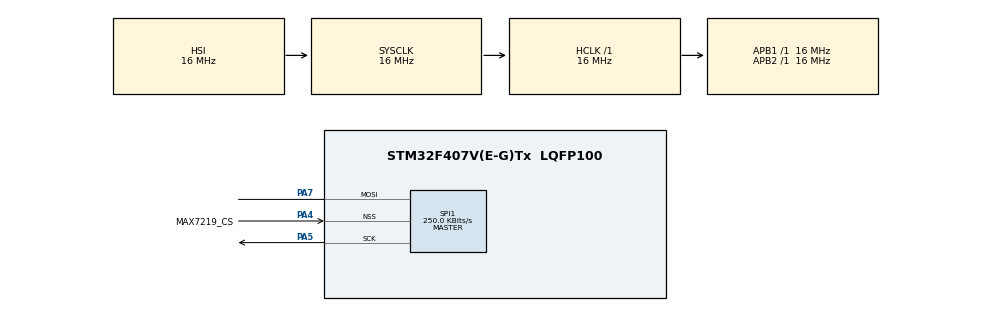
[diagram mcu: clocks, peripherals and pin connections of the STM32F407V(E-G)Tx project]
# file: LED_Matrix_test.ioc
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Mcu.Family=STM32F4
RCC.CortexFreq_Value=16000000
PA7.Mode=Simplex_Bidirectional_Master
SPI1.VirtualType=VM_MASTER
ProjectManager.StackSize=0x400
ProjectManager.TargetToolchain=STM32CubeIDE
PA4.Mode=NSS_Signal_Hard_Input
SPI1.Direction=SPI_DIRECTION_1LINE
SPI1.CalculateBaudRate=250.0 KBits/s
RCC.LSE_VALUE=32768
RCC.AHBFreq_Value=16000000
PA5.Signal=SPI1_SCK
RCC.HSE_VALUE=25000000
board=custom
RCC.VCOOutputFreq_Value=192000000
RCC.APB2Freq_Value=16000000
SPI1.Mode=SPI_MODE_MASTER
SPI1.VirtualNSS=VM_NSSHARD
Mcu.Name=STM32F407V(E-G)Tx
PA4.Signal=SPI1_NSS
RCC.SYSCLKFreq_VALUE=16000000
Mcu.Package=LQFP100
ProjectManager.HeapSize=0x200
RCC.HSI_VALUE=16000000
NVIC.PriorityGroup=NVIC_PRIORITYGROUP_4
RCC.APB1Freq_Value=16000000
SPI1.BaudRatePrescaler=SPI_BAUDRATEPRESCALER_64
PA4.GPIO_Label=MAX7219_CS
PA7.Signal=SPI1_MOSI
PA5.Mode=Simplex_Bidirectional_Master

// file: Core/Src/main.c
/* USER CODE BEGIN Header */
/**
  ******************************************************************************
  * @file           : main.c
  * @brief          : Main program body
  ******************************************************************************
  * @attention
  *
  * <h2><center>&copy; Copyright (c) 2021 STMicroelectronics.
  * All rights reserved.</center></h2>
  *
  * This software component is licensed by ST under BSD 3-Clause license,
  * the "License"; You may not use this file except in compliance with the
  * License. You may obtain a copy of the License at:
  *                        opensource.org/licenses/BSD-3-Clause
  *
  ******************************************************************************
  */
/* USER CODE END Header */
#include "main.h"

SPI_HandleTypeDef hspi1;

void SystemClock_Config(void);
static void MX_GPIO_Init(void);
static void MX_SPI1_Init(void);
/* USER CODE BEGIN PFP */
MAX7219_STATUS MAX7219_SetDisplayTest(uint8_t DeviceNumber, MAX7219_TestMode Enable);
/* USER CODE END PFP */

int main(void)
{

  /* MCU Configuration--------------------------------------------------------*/

  /* Reset of all peripherals, Initializes the Flash interface and the Systick. */
  HAL_Init();

  /* Configure the system clock */
  SystemClock_Config();

  /* Initialize all configured peripherals */
  MX_GPIO_Init();
  MX_SPI1_Init();

  /* Infinite loop */
  while (1)
  {

  }
}

void SystemClock_Config(void)
{
  RCC_OscInitTypeDef RCC_OscInitStruct = {0};
  RCC_ClkInitTypeDef RCC_ClkInitStruct = {0};

  /** Configure the main internal regulator output voltage
  */
  __HAL_RCC_PWR_CLK_ENABLE();
  __HAL_PWR_VOLTAGESCALING_CONFIG(PWR_REGULATOR_VOLTAGE_SCALE1);
  /** Initializes the RCC Oscillators according to the specified parameters
  * in the RCC_OscInitTypeDef structure.
  */
  RCC_OscInitStruct.OscillatorType = RCC_OSCILLATORTYPE_HSI;
  RCC_OscInitStruct.HSIState = RCC_HSI_ON;
  RCC_OscInitStruct.HSICalibrationValue = RCC_HSICALIBRATION_DEFAULT;
  RCC_OscInitStruct.PLL.PLLState = RCC_PLL_NONE;
  if (HAL_RCC_OscConfig(&RCC_OscInitStruct) != HAL_OK)
  {
    Error_Handler();
  }
  /** Initializes the CPU, AHB and APB buses clocks
  */
  RCC_ClkInitStruct.ClockType = RCC_CLOCKTYPE_HCLK|RCC_CLOCKTYPE_SYSCLK
                              |RCC_CLOCKTYPE_PCLK1|RCC_CLOCKTYPE_PCLK2;
  RCC_ClkInitStruct.SYSCLKSource = RCC_SYSCLKSOURCE_HSI;
  RCC_ClkInitStruct.AHBCLKDivider = RCC_SYSCLK_DIV1;
  RCC_ClkInitStruct.APB1CLKDivider = RCC_HCLK_DIV1;
  RCC_ClkInitStruct.APB2CLKDivider = RCC_HCLK_DIV1;

  if (HAL_RCC_ClockConfig(&RCC_ClkInitStruct, FLASH_LATENCY_0) != HAL_OK)
  {
    Error_Handler();
  }
}

static void MX_SPI1_Init(void)
{

  /* SPI1 parameter configuration*/
  hspi1.Instance = SPI1;
  hspi1.Init.Mode = SPI_MODE_MASTER;
  hspi1.Init.Direction = SPI_DIRECTION_1LINE;
  hspi1.Init.DataSize = SPI_DATASIZE_8BIT;
  hspi1.Init.CLKPolarity = SPI_POLARITY_LOW;
  hspi1.Init.CLKPhase = SPI_PHASE_1EDGE;
  hspi1.Init.NSS = SPI_NSS_HARD_INPUT;
  hspi1.Init.BaudRatePrescaler = SPI_BAUDRATEPRESCALER_64;
  hspi1.Init.FirstBit = SPI_FIRSTBIT_MSB;
  hspi1.Init.TIMode = SPI_TIMODE_DISABLE;
  hspi1.Init.CRCCalculation = SPI_CRCCALCULATION_DISABLE;
  hspi1.Init.CRCPolynomial = 10;
  if (HAL_SPI_Init(&hspi1) != HAL_OK)
  {
    Error_Handler();
  }

}

static void MX_GPIO_Init(void)
{

  /* GPIO Ports Clock Enable */
  __HAL_RCC_GPIOA_CLK_ENABLE();

}

void Error_Handler(void)
{
  __disable_irq();
  while (1)
  {
  }
}

/************************ (C) COPYRIGHT STMicroelectronics *****END OF FILE****/
